# MSP430FR5739 register map
File version: 1.1
CPU: msp430
Registers are 16-bit, access not given, reset 0x0 unless marked. A register's access mark holds for its fields unless they carry their own. Offsets are from the block's base; [hi:lo] are bit positions; lines under a group give offsets from that group; {n}, {i} and the like mark numbered series.

## Timer1_B3
Base 0x00000000
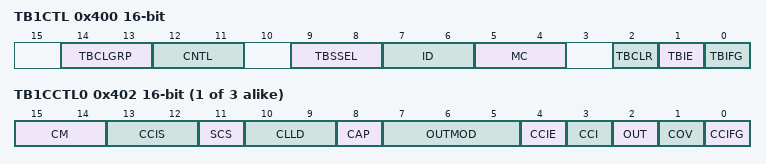
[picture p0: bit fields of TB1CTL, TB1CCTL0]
0x400 TB1CTL — Timer1_B3 Control
  [14:13] TBCLGRP — [14:13] Timer0_B7 Compare latch load group 1
    0=Timer0_B7 Group: 0 - individually; 1=Timer0_B7 Group: 1 - 3 groups (1-2; 2=Timer0_B7 Group: 2 - 2 groups (1-3; 3=Timer0_B7 Group: 3 - 1 group (all)
  [12:11] CNTL — [12:11] Counter lenght 1
    0=Counter lenght: 16 bit; 1=Counter lenght: 12 bit; 2=Counter lenght: 10 bit; 3=Counter lenght: 8 bit
  [9:8] TBSSEL — [9:8] Clock source 1
    0=Clock Source: TBCLK; 1=Clock Source: ACLK; 2=Clock Source: SMCLK; 3=Clock Source: INCLK
  [7:6] ID — [7:6] Timer0_B7 clock input divider 1
    0=Timer A input divider: 0 - /1; 1=Timer A input divider: 1 - /2; 2=Timer A input divider: 2 - /4; 3=Timer A input divider: 3 - /8
  [5:4] MC — [5:4] Timer0_B7 mode control 1
    0=Timer A mode control: 0 - Stop; 1=Timer A mode control: 1 - Up to CCR0; 2=Timer A mode control: 2 - Continuous up; 3=Timer A mode control: 3 - Up/Down
  [2] TBCLR — [2:2] Timer0_B7 counter clear
  [1] TBIE — [1:1] Timer0_B7 interrupt enable
  [0] TBIFG — [0:0] Timer0_B7 interrupt flag
{0x402+2i} TB1CCTL{i} (i=0..2) — Timer1_B3 Capture/Compare Control {i}
  [15:14] CM — [15:14] Capture mode 1
    0=Capture mode: 0 - disabled; 1=Capture mode: 1 - pos. edge; 2=Capture mode: 1 - neg. edge; 3=Capture mode: 1 - both edges
  [13:12] CCIS — [13:12] Capture input select 1
    0=Capture input select: 0 - CCIxA; 1=Capture input select: 1 - CCIxB; 2=Capture input select: 2 - GND; 3=Capture input select: 3 - Vcc
  [11] SCS — [11:11] Capture sychronize
  [10:9] CLLD — [10:9] Compare latch load source 1
    0=Compare latch load sourec : 0 - immediate; 1=Compare latch load sourec : 1 - TBR counts to 0; 2=Compare latch load sourec : 2 - up/down; 3=Compare latch load sourec : 3 - TBR counts to TBCTL0
  [8] CAP — [8:8] Capture mode: 1 /Compare mode : 0
  [7:5] OUTMOD — [7:5] Output mode 2
    0=PWM output mode: 0 - output only; 1=PWM output mode: 1 - set; 2=PWM output mode: 2 - PWM toggle/reset; 3=PWM output mode: 3 - PWM set/reset; 4=PWM output mode: 4 - toggle; 5=PWM output mode: 5 - Reset; 6=PWM output mode: 6 - PWM toggle/set; 7=PWM output mode: 7 - PWM reset/set
  [4] CCIE — [4:4] Capture/compare interrupt enable
  [3] CCI — [3:3] Capture input signal (read)
  [2] OUT — [2:2] PWM Output signal if output mode 0
  [1] COV — [1:1] Capture/compare overflow flag
  [0] CCIFG — [0:0] Capture/compare interrupt flag
0x410 TB1R — Timer1_B3
{0x412+2i} TB1CCR{i} (i=0..2) — Timer1_B3 Capture/Compare {i}
0x420 TB1EX0 — Timer1_B3 Expansion Register 0
  [2:0] TBIDEX — [2:0] Timer0_B7 Input divider expansion Bit: 0
    {v}=Timer0_B7 Input divider expansion : /{v+1} (v=0..7)
0x42E TB1IV — Timer1_B3 Interrupt Vector Word

## Timer2_B3
Base 0x00000000
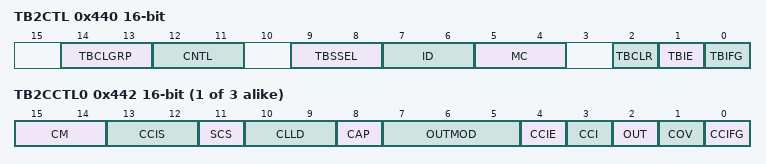
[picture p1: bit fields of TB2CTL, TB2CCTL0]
0x440 TB2CTL — Timer2_B3 Control
  [14:13] TBCLGRP — [14:13] Timer0_B7 Compare latch load group 1
    0=Timer0_B7 Group: 0 - individually; 1=Timer0_B7 Group: 1 - 3 groups (1-2; 2=Timer0_B7 Group: 2 - 2 groups (1-3; 3=Timer0_B7 Group: 3 - 1 group (all)
  [12:11] CNTL — [12:11] Counter lenght 1
    0=Counter lenght: 16 bit; 1=Counter lenght: 12 bit; 2=Counter lenght: 10 bit; 3=Counter lenght: 8 bit
  [9:8] TBSSEL — [9:8] Clock source 1
    0=Clock Source: TBCLK; 1=Clock Source: ACLK; 2=Clock Source: SMCLK; 3=Clock Source: INCLK
  [7:6] ID — [7:6] Timer0_B7 clock input divider 1
    0=Timer A input divider: 0 - /1; 1=Timer A input divider: 1 - /2; 2=Timer A input divider: 2 - /4; 3=Timer A input divider: 3 - /8
  [5:4] MC — [5:4] Timer0_B7 mode control 1
    0=Timer A mode control: 0 - Stop; 1=Timer A mode control: 1 - Up to CCR0; 2=Timer A mode control: 2 - Continuous up; 3=Timer A mode control: 3 - Up/Down
  [2] TBCLR — [2:2] Timer0_B7 counter clear
  [1] TBIE — [1:1] Timer0_B7 interrupt enable
  [0] TBIFG — [0:0] Timer0_B7 interrupt flag
{0x442+2i} TB2CCTL{i} (i=0..2) — Timer2_B3 Capture/Compare Control {i}
  [15:14] CM — [15:14] Capture mode 1
    0=Capture mode: 0 - disabled; 1=Capture mode: 1 - pos. edge; 2=Capture mode: 1 - neg. edge; 3=Capture mode: 1 - both edges
  [13:12] CCIS — [13:12] Capture input select 1
    0=Capture input select: 0 - CCIxA; 1=Capture input select: 1 - CCIxB; 2=Capture input select: 2 - GND; 3=Capture input select: 3 - Vcc
  [11] SCS — [11:11] Capture sychronize
  [10:9] CLLD — [10:9] Compare latch load source 1
    0=Compare latch load sourec : 0 - immediate; 1=Compare latch load sourec : 1 - TBR counts to 0; 2=Compare latch load sourec : 2 - up/down; 3=Compare latch load sourec : 3 - TBR counts to TBCTL0
  [8] CAP — [8:8] Capture mode: 1 /Compare mode : 0
  [7:5] OUTMOD — [7:5] Output mode 2
    0=PWM output mode: 0 - output only; 1=PWM output mode: 1 - set; 2=PWM output mode: 2 - PWM toggle/reset; 3=PWM output mode: 3 - PWM set/reset; 4=PWM output mode: 4 - toggle; 5=PWM output mode: 5 - Reset; 6=PWM output mode: 6 - PWM toggle/set; 7=PWM output mode: 7 - PWM reset/set
  [4] CCIE — [4:4] Capture/compare interrupt enable
  [3] CCI — [3:3] Capture input signal (read)
  [2] OUT — [2:2] PWM Output signal if output mode 0
  [1] COV — [1:1] Capture/compare overflow flag
  [0] CCIFG — [0:0] Capture/compare interrupt flag
0x450 TB2R — Timer2_B3
{0x452+2i} TB2CCR{i} (i=0..2) — Timer2_B3 Capture/Compare {i}
0x460 TB2EX0 — Timer2_B3 Expansion Register 0
  [2:0] TBIDEX — [2:0] Timer0_B7 Input divider expansion Bit: 0
    {v}=Timer0_B7 Input divider expansion : /{v+1} (v=0..7)
0x46E TB2IV — Timer2_B3 Interrupt Vector Word
